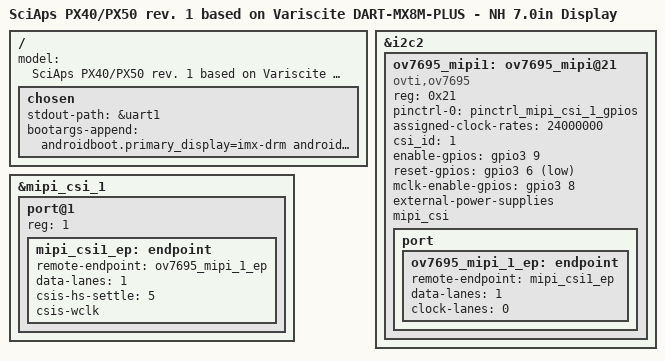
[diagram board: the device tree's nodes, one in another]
// SPDX-License-Identifier: (GPL-2.0+ OR MIT)
/*
 * Copyright 2019 NXP
 * Copyright 2020-2023 Variscite Ltd.
 * Copyright 2025 SciAps
 */

#include "imx8mp-var-dart-sciaps-btx.dtsi"

/ {
	model = "SciAps PX40/PX50 rev. 1 based on Variscite DART-MX8M-PLUS - NH 7.0in Display";
	chosen {
		stdout-path = &uart1;
		//console=ttymxc0,115200 earlycon=ec_imx6q,0x30860000,1/15200 androidboot.console=ttymxc0
		bootargs-append = "androidboot.primary_display=imx-drm androidboot.camera.layout=ov5645-ov7695 androidboot.sciaps.lcd_density=160 androidboot.sciaps.btx.model=PX40/PX50 moal.mod_para=wifi_mod_para_iw612.conf"; // wifi_mod_para_iw612.conf wifi_mod_para_sd8987.conf
	};
};

&i2c2 {
	ov7695_mipi1: ov7695_mipi@21 {
		compatible = "ovti,ov7695";
		reg = <0x21>;
		pinctrl-names = "default";
		pinctrl-0 = <&pinctrl_mipi_csi_1_gpios>;
#if 0
		// Disabled as the board uses its own oscillator.
		clocks = <&clk IMX8MP_CLK_IPP_DO_CLKO2>;
		clock-names = "xclk";
		assigned-clocks = <&clk IMX8MP_CLK_IPP_DO_CLKO2>;
		assigned-clock-parents = <&clk IMX8MP_CLK_24M>;
		clock-frequency = <24000000>;
		mclk = <24000000>;
		mclk_source = <0>;
#endif
		assigned-clock-rates = <24000000>;
		csi_id = <1>;
		enable-gpios = <&gpio3 9 GPIO_ACTIVE_HIGH>;
		reset-gpios = <&gpio3 6 GPIO_ACTIVE_LOW>;
		mclk-enable-gpios = <&gpio3 8 GPIO_ACTIVE_HIGH>;
		external-power-supplies;
		mipi_csi;
		status = "okay";

		port {
			ov7695_mipi_1_ep: endpoint {
				remote-endpoint = <&mipi_csi1_ep>;
				data-lanes = <1>;
				clock-lanes = <0>;
			};
		};
	};
};

&mipi_csi_1 {
	#address-cells = <1>;
	#size-cells = <0>;
	status = "okay";

	port@1 {
		reg = <1>;
		mipi_csi1_ep: endpoint {
			remote-endpoint = <&ov7695_mipi_1_ep>;
			data-lanes = <1>;
			//csis-hs-settle = <13>;
			//csis-clk-settle = <2>;
			csis-hs-settle = <5>;
			csis-wclk;
		};
	};
};

#include "imx8mp-android.dtsi"
